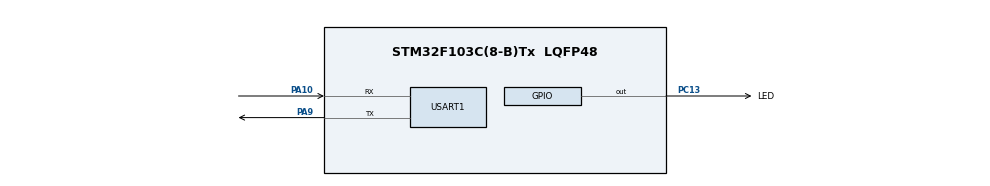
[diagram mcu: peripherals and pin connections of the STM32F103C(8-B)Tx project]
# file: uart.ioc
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Mcu.Family=STM32F1
Mcu.Name=STM32F103C(8-B)Tx
Mcu.Package=LQFP48
NVIC.PriorityGroup=NVIC_PRIORITYGROUP_4
PA10.Mode=Asynchronous
PA10.Signal=USART1_RX
PA13.Mode=Serial_Wire
PA13.Signal=SYS_JTMS-SWDIO
PA14.Mode=Serial_Wire
PA14.Signal=SYS_JTCK-SWCLK
PA9.Mode=Asynchronous
PA9.Signal=USART1_TX
PC13-TAMPER-RTC.GPIO_Label=LED
PC13-TAMPER-RTC.Signal=GPIO_Output
ProjectManager.HeapSize=0x200
ProjectManager.StackSize=0x400
ProjectManager.TargetToolchain=MDK-ARM V5.32
RCC.APB1Freq_Value=8000000
RCC.APB2Freq_Value=8000000
USART1.VirtualMode=VM_ASYNC
board=custom

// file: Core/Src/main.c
/* USER CODE BEGIN Header */
/**
  ******************************************************************************
  * @file           : main.c
  * @brief          : Main program body
  ******************************************************************************
  * @attention
  *
  * Copyright (c) 2025 STMicroelectronics.
  * All rights reserved.
  *
  * This software is licensed under terms that can be found in the LICENSE file
  * in the root directory of this software component.
  * If no LICENSE file comes with this software, it is provided AS-IS.
  *
  ******************************************************************************
  */
/* USER CODE END Header */
#include "main.h"
#include "usart.h"
#include "gpio.h"

/* USER CODE BEGIN Includes */

#include <string.h>

/* USER CODE END Includes */

void SystemClock_Config(void);

int main(void)
{

  /* MCU Configuration--------------------------------------------------------*/

  /* Reset of all peripherals, Initializes the Flash interface and the Systick. */
  HAL_Init();

  /* Configure the system clock */
  SystemClock_Config();

  /* Initialize all configured peripherals */
  MX_GPIO_Init();
  MX_USART1_UART_Init();
  /* USER CODE BEGIN 2 */

  uint8_t ab = 0x5a;
  if (HAL_UART_Transmit(&huart1, &ab, 1, HAL_MAX_DELAY) != HAL_OK)
  {

    Error_Handler();
  }

  /* USER CODE END 2 */

  /* Infinite loop */
  while (1)
  {

    /* USER CODE BEGIN 3 */

		HAL_GPIO_WritePin(GPIOC,GPIO_PIN_13,GPIO_PIN_SET);

		uint8_t data;

    uint16_t a ;
    uint16_t b ;

		HAL_UART_Receive(&huart1,&data,6,HAL_MAX_DELAY);

    if(data >= 100)
    {
      //HAL_GPIO_WritePin(GPIOC,GPIO_PIN_13,GPIO_PIN_SET);
        a++;
    }
    else if(data < 100)
    {
      //HAL_GPIO_WritePin(GPIOC,GPIO_PIN_13,GPIO_PIN_RESET);
			b ++;

    }

  }
  /* USER CODE END 3 */
}

void SystemClock_Config(void)
{
  RCC_OscInitTypeDef RCC_OscInitStruct = {0};
  RCC_ClkInitTypeDef RCC_ClkInitStruct = {0};

  /** Initializes the RCC Oscillators according to the specified parameters
  * in the RCC_OscInitTypeDef structure.
  */
  RCC_OscInitStruct.OscillatorType = RCC_OSCILLATORTYPE_HSI;
  RCC_OscInitStruct.HSIState = RCC_HSI_ON;
  RCC_OscInitStruct.HSICalibrationValue = RCC_HSICALIBRATION_DEFAULT;
  RCC_OscInitStruct.PLL.PLLState = RCC_PLL_NONE;
  if (HAL_RCC_OscConfig(&RCC_OscInitStruct) != HAL_OK)
  {
    Error_Handler();
  }

  /** Initializes the CPU, AHB and APB buses clocks
  */
  RCC_ClkInitStruct.ClockType = RCC_CLOCKTYPE_HCLK|RCC_CLOCKTYPE_SYSCLK
                              |RCC_CLOCKTYPE_PCLK1|RCC_CLOCKTYPE_PCLK2;
  RCC_ClkInitStruct.SYSCLKSource = RCC_SYSCLKSOURCE_HSI;
  RCC_ClkInitStruct.AHBCLKDivider = RCC_SYSCLK_DIV1;
  RCC_ClkInitStruct.APB1CLKDivider = RCC_HCLK_DIV1;
  RCC_ClkInitStruct.APB2CLKDivider = RCC_HCLK_DIV1;

  if (HAL_RCC_ClockConfig(&RCC_ClkInitStruct, FLASH_LATENCY_0) != HAL_OK)
  {
    Error_Handler();
  }
}

/* USER CODE BEGIN 4 */

#define BUFFER_SIZE 256
uint8_t buffer[BUFFER_SIZE];
uint16_t buffer_index = 0;
uint16_t a = 0;
uint16_t b = 0;

void receive_char()
{
    uint8_t data;
    if (HAL_UART_Receive(&huart1, &data, 1, HAL_MAX_DELAY) == HAL_OK) {
        if (data == '\n')
					{
            if (buffer_index > 0)
						{

                int value = 0;
                for (int i = 0; i < buffer_index; i++)
								{
                    value = value * 10 + (buffer[i] - '0');
                }
                if (value >= 100)
									{
                    a++;
                } else {
                    b++;
                }
            }
            buffer_index = 0;  // ???????
        } else {
            if (buffer_index < BUFFER_SIZE - 1) {
                buffer[buffer_index++] = data;
            }
        }
    }
}

/* USER CODE END 4 */

void Error_Handler(void)
{
  __disable_irq();
  while (1)
  {
  }
}
